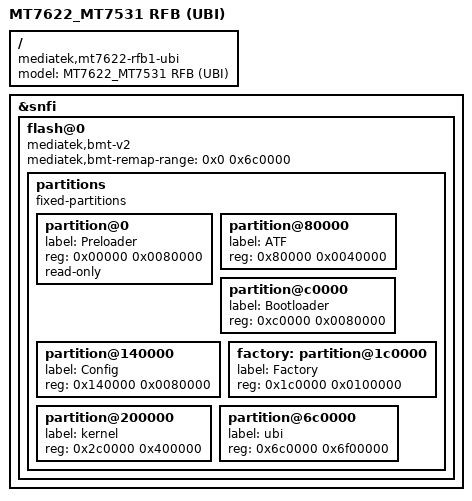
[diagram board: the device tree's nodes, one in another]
/dts-v1/;

#include "mt7622-rfb1.dts"
/ {
	model = "MT7622_MT7531 RFB (UBI)";
	compatible = "mediatek,mt7622-rfb1-ubi";
};

&snfi {
	flash@0 {
		mediatek,bmt-v2;
		mediatek,bmt-remap-range = <0x0 0x6c0000>;

		partitions {
			compatible = "fixed-partitions";
			#address-cells = <1>;
			#size-cells = <1>;

			partition@0 {
				label = "Preloader";
				reg = <0x00000 0x0080000>;
				read-only;
			};

			partition@80000 {
				label = "ATF";
				reg = <0x80000 0x0040000>;
			};

			partition@c0000 {
				label = "Bootloader";
				reg = <0xc0000 0x0080000>;
			};

			partition@140000 {
				label = "Config";
				reg = <0x140000 0x0080000>;
			};

			factory: partition@1c0000 {
				label = "Factory";
				reg = <0x1c0000 0x0100000>;
			};

			partition@200000 {
				label = "kernel";
				reg = <0x2c0000 0x400000>;
			};

			partition@6c0000 {
				label = "ubi";
				reg = <0x6c0000 0x6f00000>;
			};

			/delete-node/ partition@2200000;
		};
	};
};
